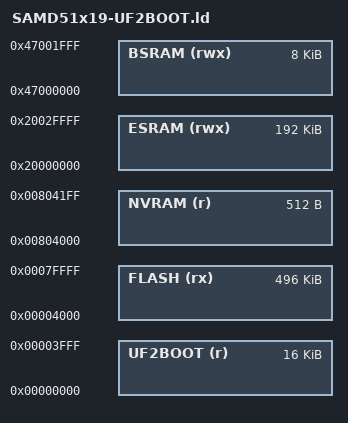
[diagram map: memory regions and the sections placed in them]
/* UF2 bootloader on M4 boards uses 16K */
UF2BOOT_SIZE = 16K;

MEMORY
{
    UF2BOOT(r) : ORIGIN = 0x00000000, LENGTH = UF2BOOT_SIZE
    FLASH(rx)  : ORIGIN = 0x00004000, LENGTH = 512K - UF2BOOT_SIZE
    NVRAM(r)   : ORIGIN = 0x00804000, LENGTH = 512
    ESRAM(rwx) : ORIGIN = 0x20000000, LENGTH = 192K
    BSRAM(rwx) : ORIGIN = 0x47000000, LENGTH = 8K
}

STACK_SIZE = DEFINED(STACK_SIZE) ? STACK_SIZE : DEFINED(__stack_size__) ? __stack_size__ : 32K;

SEARCH_DIR(.)
INCLUDE SAMD51.ld
